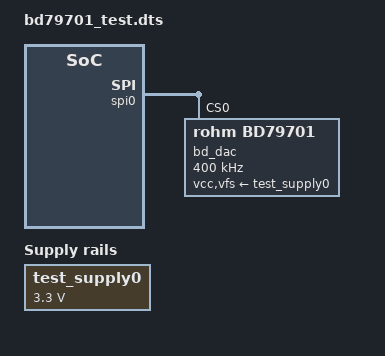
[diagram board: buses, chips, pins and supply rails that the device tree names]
/dts-v1/;
/plugin/;

#include <dt-bindings/pinctrl/omap.h>
#include <dt-bindings/pinctrl/am33xx.h>

/* SPI1 */
/* D1 Output and D0 Input */
/ {
    compatible = "ti,beaglebone", "ti,beaglebone-black";

    /* identification */
    /* part-number = "spi1mux"; */
   part-number = "spi1pinmux";


    fragment@1 {
        target-path = "/";
        __overlay__ {
		test_supply0: test_reg0 {
			compatible = "regulator-fixed";
			regulator-name = "test-reg0";
			regulator-min-microvolt = <3300000>;
			regulator-max-microvolt = <3300000>;
		};
        };
    };

    fragment@2 {
        target = <&spi0>;
        __overlay__ {
		bd_dac: bd_dac@0 { /* the "test" defined as child of the i2c1 bus */
			compatible = "rohm,bd79701";
			reg = <0>;
			/* spi-max-frequency = <4300000>; */
			spi-max-frequency = <400000>;
			vcc-supply = <&test_supply0>;
			vfs-supply = <&test_supply0>;
		};
	};
    };
};
